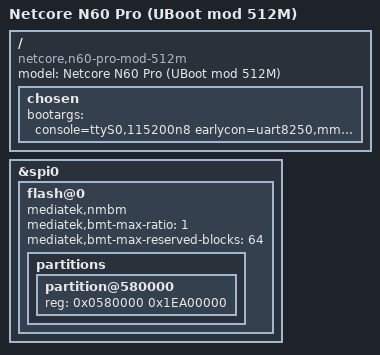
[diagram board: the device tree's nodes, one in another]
// SPDX-License-Identifier: GPL-2.0-or-later OR MIT

/dts-v1/;

#include "mt7986a-netcore-n60-pro.dts"

/ {
	model = "Netcore N60 Pro (UBoot mod 512M)";
	compatible = "netcore,n60-pro-mod-512m", "mediatek,mt7986a";

	chosen {
		bootargs = "console=ttyS0,115200n8 earlycon=uart8250,mmio32,0x11002000";
		/delete-property/ rootdisk;
	};
};

&spi0 {
	flash@0 {
		mediatek,nmbm;
		mediatek,bmt-max-ratio = <1>;
		mediatek,bmt-max-reserved-blocks = <64>;
		partitions {
			partition@580000 {
				reg = <0x0580000 0x1EA00000>;
				/delete-property/ compatible;
				/delete-node/ volumes;
			};
		};
	};
};
